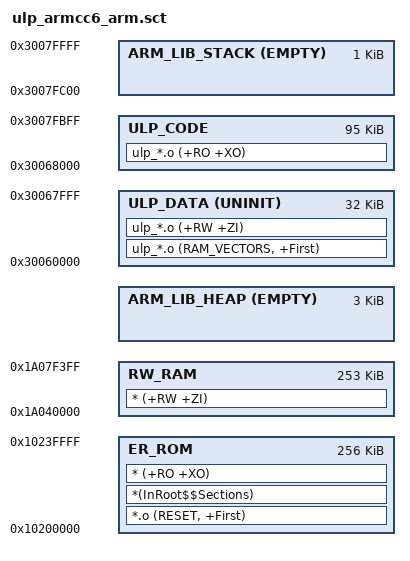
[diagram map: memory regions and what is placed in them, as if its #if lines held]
#! armclang -E --target=arm-arm-none-eabi -mcpu=cortex-m33 -xc
; command above MUST be in first line (no comment above!)

#if defined QSPI
  #define S_CODE_START   0x10200000
  #define S_CODE_SIZE    0x00040000
#elif defined MRAM
  #define S_CODE_START   0x1A000000
  #define S_CODE_SIZE    0x00040000
#else
  #error Please #define QSPI or MRAM!
#endif

#define S_DATA_START   0x1A040000
#define S_DATA_SIZE    0x00040000


#define __STACK_SIZE   0x00000400
#define __HEAP_SIZE    0x00000C00


/*----------------------------------------------------------------------------
  SRAM3 = ULP Memory (not switched off during power down)
 *----------------------------------------------------------------------------*/
#define ULP_RAM_START         0x30060000
#define ULP_RAM_SIZE          0x00020000
#define ULP_RAM_DATA_START    (ULP_RAM_START)
#define ULP_RAM_DATA_SIZE     0x00008000
#define ULP_RAM_CODE_START    (ULP_RAM_DATA_START + ULP_RAM_DATA_SIZE)
#define ULP_RAM_CODE_SIZE     (ULP_RAM_SIZE - ULP_RAM_DATA_SIZE - __STACK_SIZE)


/*----------------------------------------------------------------------------
  Scatter File Definitions
 *----------------------------------------------------------------------------*/
#define __RO_BASE         S_CODE_START
#define __RO_SIZE         S_CODE_SIZE

#define __RW_BASE         S_DATA_START
#define __RW_SIZE        (S_DATA_SIZE - __HEAP_SIZE)

#define __STACK_TOP      (ULP_RAM_START + ULP_RAM_SIZE)   /* starts at end of ULP_RAM */
#define __HEAP_BASE      (AlignExpr(+0, 8))               /* starts after the section before (RW_RAM section), 8 byte aligned */


LR_ROM __RO_BASE __RO_SIZE  {                       ; load region size_region
  ER_ROM __RO_BASE __RO_SIZE  {                     ; load address = execution address
    *.o (RESET, +First)
    *(InRoot$$Sections)
//    *(Veneer$$CMSE)                               ; uncomment to locate SG veneers
    * (+RO +XO)
  }

  ULP_DATA ULP_RAM_DATA_START UNINIT ULP_RAM_DATA_SIZE  {
    ulp_*.o (RAM_VECTORS, +First)
    ulp_*.o (+RW +ZI)
  }
  ULP_CODE ULP_RAM_CODE_START        ULP_RAM_CODE_SIZE  {
    ulp_*.o (+RO +XO)
  }

  RW_RAM __RW_BASE __RW_SIZE  {                     ; RW data
    * (+RW +ZI)
  }

  ARM_LIB_HEAP  __HEAP_BASE EMPTY  __HEAP_SIZE  {   ; Reserve empty region for heap
  }

  ARM_LIB_STACK __STACK_TOP EMPTY -__STACK_SIZE {   ; Reserve empty region for stack
  }
}
